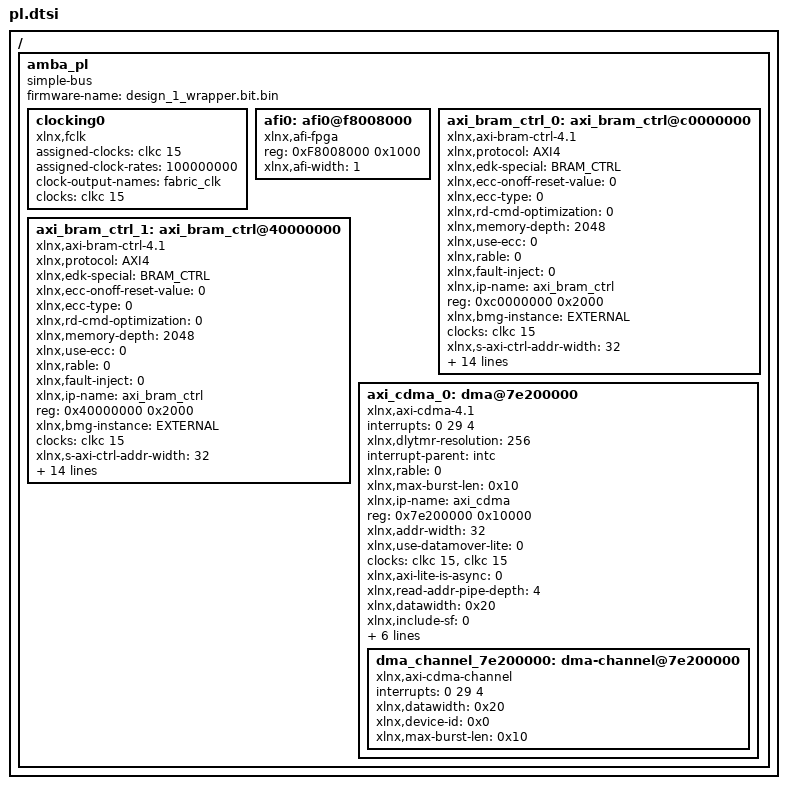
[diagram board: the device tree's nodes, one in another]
/ {
	amba_pl: amba_pl {
		ranges;
		compatible = "simple-bus";
		#address-cells = <1>;
		#size-cells = <1>;
		firmware-name = "design_1_wrapper.bit.bin";
		clocking0: clocking0 {
			compatible = "xlnx,fclk";
			assigned-clocks = <&clkc 15>;
			assigned-clock-rates = <100000000>;
			#clock-cells = <0>;
			clock-output-names = "fabric_clk";
			clocks = <&clkc 15>;
		};
		afi0: afi0@f8008000 {
			status = "okay";
			compatible = "xlnx,afi-fpga";
			#address-cells = <1>;
			reg = <0xF8008000 0x1000>;
			#size-cells = <0>;
			xlnx,afi-width = <1>;
		};
		axi_bram_ctrl_0: axi_bram_ctrl@c0000000 {
			xlnx,protocol = "AXI4";
			xlnx,edk-special = "BRAM_CTRL";
			compatible = "xlnx,axi-bram-ctrl-4.1";
			xlnx,ecc-onoff-reset-value = <0>;
			xlnx,ecc-type = <0>;
			xlnx,rd-cmd-optimization = <0>;
			xlnx,memory-depth = <2048>;
			xlnx,use-ecc = <0>;
			xlnx,rable = <0>;
			xlnx,fault-inject = <0>;
			xlnx,ip-name = "axi_bram_ctrl";
			reg = <0xc0000000 0x2000>;
			xlnx,bmg-instance = "EXTERNAL";
			clocks = <&clkc 15>;
			xlnx,s-axi-ctrl-addr-width = <32>;
			xlnx,read-latency = <1>;
			xlnx,id-width = <0>;
			xlnx,s-axi-supports-narrow-burst = <0>;
			xlnx,supports-narrow-burst = <0>;
			xlnx,single-port-bram = <1>;
			xlnx,ecc = <0>;
			xlnx,edk-iptype = "PERIPHERAL";
			status = "okay";
			clock-names = "s_axi_aclk";
			xlnx,data-width = <32>;
			xlnx,bram-addr-width = <11>;
			xlnx,bram-inst-mode = "EXTERNAL";
			xlnx,s-axi-ctrl-data-width = <32>;
			xlnx,mem-depth = <2048>;
			xlnx,s-axi-id-width = <1>;
			xlnx,name = "axi_bram_ctrl_0";
		};
		axi_bram_ctrl_1: axi_bram_ctrl@40000000 {
			xlnx,protocol = "AXI4";
			xlnx,edk-special = "BRAM_CTRL";
			compatible = "xlnx,axi-bram-ctrl-4.1";
			xlnx,ecc-onoff-reset-value = <0>;
			xlnx,ecc-type = <0>;
			xlnx,rd-cmd-optimization = <0>;
			xlnx,memory-depth = <2048>;
			xlnx,use-ecc = <0>;
			xlnx,rable = <0>;
			xlnx,fault-inject = <0>;
			xlnx,ip-name = "axi_bram_ctrl";
			reg = <0x40000000 0x2000>;
			xlnx,bmg-instance = "EXTERNAL";
			clocks = <&clkc 15>;
			xlnx,s-axi-ctrl-addr-width = <32>;
			xlnx,read-latency = <1>;
			xlnx,id-width = <0>;
			xlnx,s-axi-supports-narrow-burst = <0>;
			xlnx,supports-narrow-burst = <0>;
			xlnx,single-port-bram = <1>;
			xlnx,ecc = <0>;
			xlnx,edk-iptype = "PERIPHERAL";
			status = "okay";
			clock-names = "s_axi_aclk";
			xlnx,data-width = <32>;
			xlnx,bram-addr-width = <11>;
			xlnx,bram-inst-mode = "EXTERNAL";
			xlnx,s-axi-ctrl-data-width = <32>;
			xlnx,mem-depth = <2048>;
			xlnx,s-axi-id-width = <1>;
			xlnx,name = "axi_bram_ctrl_1";
		};
		axi_cdma_0: dma@7e200000 {
			interrupts = < 0 29 4 >;
			compatible = "xlnx,axi-cdma-4.1" , "xlnx,axi-cdma-1.00.a";
			xlnx,dlytmr-resolution = <256>;
			interrupt-parent = <&intc>;
			xlnx,rable = <0>;
			#dma-cells = <1>;
			xlnx,max-burst-len = <0x10>;
			xlnx,ip-name = "axi_cdma";
			reg = <0x7e200000 0x10000>;
			xlnx,addr-width = <32>;
			xlnx,use-datamover-lite = <0>;
			clocks = <&clkc 15>, <&clkc 15>;
			xlnx,axi-lite-is-async = <0>;
			xlnx,read-addr-pipe-depth = <4>;
			xlnx,datawidth = <0x20>;
			xlnx,include-sf = <0>;
			xlnx,addrwidth = <0x20>;
			xlnx,edk-iptype = "PERIPHERAL";
			xlnx,include-dre = <0x0>;
			status = "okay";
			clock-names = "m_axi_aclk" , "s_axi_lite_aclk";
			xlnx,lite-mode = <0x0>;
			interrupt-names = "cdma_introut";
			xlnx,write-addr-pipe-depth = <4>;
			xlnx,name = "axi_cdma_0";
			dma_channel_7e200000: dma-channel@7e200000 {
				interrupts = < 0 29 4 >;
				xlnx,datawidth = <0x20>;
				xlnx,device-id = <0x0>;
				compatible = "xlnx,axi-cdma-channel";
				xlnx,max-burst-len = <0x10>;
			};
		};
	};
};
